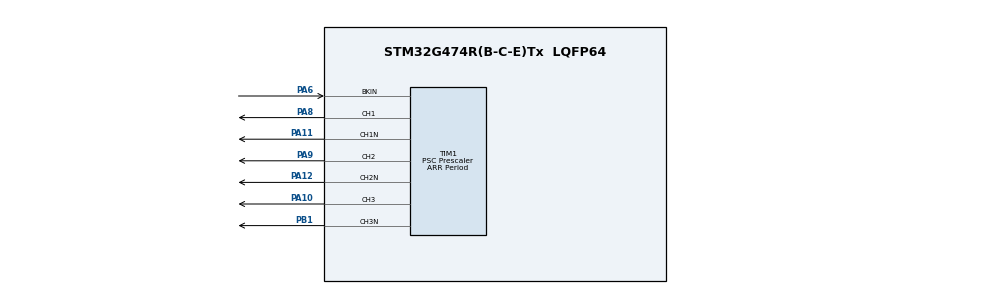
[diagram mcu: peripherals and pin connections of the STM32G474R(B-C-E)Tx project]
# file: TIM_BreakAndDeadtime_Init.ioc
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Mcu.Family=STM32G4
Mcu.Name=STM32G474R(B-C-E)Tx
Mcu.Package=LQFP64
NVIC.PriorityGroup=NVIC_PRIORITYGROUP_4
PA10.GPIO_Speed=GPIO_SPEED_FREQ_HIGH
PA10.Signal=S_TIM1_CH3
PA11.GPIO_Speed=GPIO_SPEED_FREQ_HIGH
PA11.Mode=PWM Generation1 CH1 CH1N
PA11.Signal=TIM1_CH1N
PA12.GPIO_Speed=GPIO_SPEED_FREQ_HIGH
PA12.Mode=PWM Generation2 CH2 CH2N
PA12.Signal=TIM1_CH2N
PA6.GPIO_PuPd=GPIO_PULLDOWN
PA6.GPIO_PuPdOD=GPIO_PULLDOWN
PA6.Mode=Activate-Break-Input
PA6.Signal=TIM1_BKIN
PA8.GPIO_Speed=GPIO_SPEED_FREQ_HIGH
PA8.Signal=S_TIM1_CH1
PA9.GPIO_Speed=GPIO_SPEED_FREQ_HIGH
PA9.Signal=S_TIM1_CH2
PB1.GPIO_Speed=GPIO_SPEED_FREQ_HIGH
PB1.Mode=PWM Generation3 CH3 CH3N
PB1.Signal=TIM1_CH3N
ProjectManager.HeapSize=0x200
ProjectManager.StackSize=0x400
ProjectManager.TargetToolchain=EWARM V8.32
RCC.ADC12Freq_Value=170000000
RCC.ADC345Freq_Value=170000000
RCC.AHBFreq_Value=170000000
RCC.APB1Freq_Value=170000000
RCC.APB1TimFreq_Value=170000000
RCC.APB2Freq_Value=170000000
RCC.APB2TimFreq_Value=170000000
RCC.CortexFreq_Value=170000000
RCC.EXTERNAL_CLOCK_VALUE=12288000
RCC.HCLKFreq_Value=170000000
RCC.HSE_VALUE=24000000
RCC.HSI48_VALUE=48000000
RCC.HSI_VALUE=16000000
RCC.LSE_VALUE=32768
RCC.PLLM=RCC_PLLM_DIV4
RCC.PLLN=85
RCC.SYSCLKFreq_VALUE=170000000
RCC.SYSCLKSource=RCC_SYSCLKSOURCE_PLLCLK
RCC.USBFreq_Value=170000000
RCC.VCOOutputFreq_Value=340000000
SH.S_TIM1_CH1.0=TIM1_CH1,PWM Generation1 CH1 CH1N
SH.S_TIM1_CH2.0=TIM1_CH2,PWM Generation2 CH2 CH2N
SH.S_TIM1_CH3.0=TIM1_CH3,PWM Generation3 CH3 CH3N
TIM1.AsymmetricalDeadTime=DISABLE
TIM1.AutoReloadPreload=TIM_AUTORELOAD_PRELOAD_DISABLE
TIM1.AutomaticOutput=TIM_AUTOMATICOUTPUT_ENABLE
TIM1.Break2Filter=0
TIM1.Break2Polarity=TIM_BREAK2POLARITY_HIGH
TIM1.Break2State=TIM_BREAK2_DISABLE
TIM1.BreakAFMode=TIM_BREAK_AFMODE_INPUT
TIM1.BreakFilter=0
TIM1.BreakPolarity=TIM_BREAKPOLARITY_HIGH
TIM1.BreakState=TIM_BREAK_ENABLE
TIM1.Channel-PWM\ Generation1\ CH1\ CH1N=TIM_CHANNEL_1
TIM1.Channel-PWM\ Generation2\ CH2\ CH2N=TIM_CHANNEL_2
TIM1.Channel-PWM\ Generation3\ CH3\ CH3N=TIM_CHANNEL_3
TIM1.ClearInputSource=TIM_CLEARINPUTSOURCE_NONE
TIM1.ClockDivision=TIM_CLOCKDIVISION_DIV1
TIM1.CounterMode=TIM_COUNTERMODE_CENTERALIGNED1
TIM1.DeadTime=Deadtime
TIM1.DeadTimePreload=DISABLE
TIM1.Dithering=Disable
TIM1.LockLevel=TIM_LOCKLEVEL_1
TIM1.OCFastMode_PWM-PWM\ Generation1\ CH1\ CH1N=TIM_OCFAST_DISABLE
TIM1.OCFastMode_PWM-PWM\ Generation2\ CH2\ CH2N=TIM_OCFAST_DISABLE
TIM1.OCFastMode_PWM-PWM\ Generation3\ CH3\ CH3N=TIM_OCFAST_DISABLE
TIM1.OCIdleState_1=TIM_OCIDLESTATE_RESET
TIM1.OCIdleState_2=TIM_OCIDLESTATE_RESET
TIM1.OCIdleState_3=TIM_OCIDLESTATE_RESET
TIM1.OCMode_PWM-PWM\ Generation1\ CH1\ CH1N=TIM_OCMODE_PWM1
TIM1.OCMode_PWM-PWM\ Generation2\ CH2\ CH2N=TIM_OCMODE_PWM1
TIM1.OCMode_PWM-PWM\ Generation3\ CH3\ CH3N=TIM_OCMODE_PWM1
TIM1.OCNIdleState_1=TIM_OCNIDLESTATE_RESET
TIM1.OCNIdleState_2=TIM_OCNIDLESTATE_RESET
TIM1.OCNIdleState_3=TIM_OCNIDLESTATE_RESET
TIM1.OCNPolarity_1=TIM_OCNPOLARITY_HIGH
TIM1.OCNPolarity_2=TIM_OCNPOLARITY_HIGH
TIM1.OCNPolarity_3=TIM_OCNPOLARITY_HIGH
TIM1.OCPolarity_1=TIM_OCPOLARITY_HIGH
TIM1.OCPolarity_2=TIM_OCPOLARITY_HIGH
TIM1.OCPolarity_3=TIM_OCPOLARITY_HIGH
TIM1.OffStateIDLEMode=TIM_OSSI_ENABLE
TIM1.OffStateRunMode=TIM_OSSR_ENABLE
TIM1.PeriodNoDither=Period
TIM1.Prescaler=Prescaler
TIM1.PulseNoDither_1=Pulse1
TIM1.PulseNoDither_2=Pulse2
TIM1.PulseNoDither_3=Pulse3
TIM1.RepetitionCounter=0
TIM1.SourceBRK2COMP1=TIM_BREAKINPUTSOURCE_DISABLE
TIM1.SourceBRK2COMP2=TIM_BREAKINPUTSOURCE_DISABLE
TIM1.SourceBRK2COMP3=TIM_BREAKINPUTSOURCE_DISABLE
TIM1.SourceBRK2COMP4=TIM_BREAKINPUTSOURCE_DISABLE
TIM1.SourceBRK2COMP5=TIM_BREAKINPUTSOURCE_DISABLE
TIM1.SourceBRK2COMP6=TIM_BREAKINPUTSOURCE_DISABLE
TIM1.SourceBRK2COMP7=TIM_BREAKINPUTSOURCE_DISABLE
TIM1.SourceBRK2DigInput=TIM_BREAKINPUTSOURCE_DISABLE
TIM1.SourceBRKCOMP1=TIM_BREAKINPUTSOURCE_DISABLE
TIM1.SourceBRKCOMP2=TIM_BREAKINPUTSOURCE_DISABLE
TIM1.SourceBRKCOMP3=TIM_BREAKINPUTSOURCE_DISABLE
TIM1.SourceBRKCOMP4=TIM_BREAKINPUTSOURCE_DISABLE
TIM1.SourceBRKCOMP5=TIM_BREAKINPUTSOURCE_DISABLE
TIM1.SourceBRKCOMP6=TIM_BREAKINPUTSOURCE_DISABLE
TIM1.SourceBRKCOMP7=TIM_BREAKINPUTSOURCE_DISABLE
TIM1.SourceBRKDigInput=TIM_BREAKINPUTSOURCE_ENABLE
TIM1.SourceBRKDigInputPolarity=TIM_BREAKINPUTSOURCE_POLARITY_HIGH
TIM1.TIM_MasterOutputTrigger=TIM_TRGO_RESET
TIM1.TIM_MasterOutputTrigger2=TIM_TRGO2_RESET
TIM1.TIM_MasterSlaveMode=TIM_MASTERSLAVEMODE_DISABLE
VP_SYS_VS_DBSignals.Mode=DisableDeadBatterySignals
board=custom

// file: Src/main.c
/* USER CODE BEGIN Header */
/**
  ******************************************************************************
  * @file           : main.c
  * @brief          : Main program body
  ******************************************************************************
  * @attention
  *
  * Copyright (c) 2019-2021 STMicroelectronics.
  * All rights reserved.
  *
  * This software is licensed under terms that can be found in the LICENSE file
  * in the root directory of this software component.
  * If no LICENSE file comes with this software, it is provided AS-IS.
  *
  ******************************************************************************
  */
/* USER CODE END Header */
#include "main.h"

void SystemClock_Config(void);
static void MX_GPIO_Init(void);
static void MX_TIM1_Init(void);

int main(void)
{

  /* MCU Configuration--------------------------------------------------------*/

  /* Reset of all peripherals, Initializes the Flash interface and the Systick. */

  LL_APB2_GRP1_EnableClock(LL_APB2_GRP1_PERIPH_SYSCFG);
  LL_APB1_GRP1_EnableClock(LL_APB1_GRP1_PERIPH_PWR);

  NVIC_SetPriorityGrouping(NVIC_PRIORITYGROUP_4);

  /* System interrupt init*/

  /** Disable the internal Pull-Up in Dead Battery pins of UCPD peripheral
  */
  LL_PWR_DisableUCPDDeadBattery();

  /* Configure the system clock */
  SystemClock_Config();

  /* Initialize all configured peripherals */
  MX_GPIO_Init();
  MX_TIM1_Init();
  /* USER CODE BEGIN 2 */

  /**********************************/
  /* Start output signal generation */
  /**********************************/
  /* Enable outputs OC1, OC1N, OC2, OC2N, OC3 and OC3N */
  LL_TIM_CC_EnableChannel(TIM1, LL_TIM_CHANNEL_CH1  |
                                LL_TIM_CHANNEL_CH1N |
                                LL_TIM_CHANNEL_CH2  |
                                LL_TIM_CHANNEL_CH2N |
                                LL_TIM_CHANNEL_CH3  |
                                LL_TIM_CHANNEL_CH3N);

  /* Enable counter */
  LL_TIM_EnableCounter(TIM1);

  /* Force update generation */
  LL_TIM_GenerateEvent_UPDATE(TIM1);

  /* USER CODE END 2 */

  /* Infinite loop */
  while (1)
  {

  }
}

void SystemClock_Config(void)
{
  LL_FLASH_SetLatency(LL_FLASH_LATENCY_4);
  while(LL_FLASH_GetLatency() != LL_FLASH_LATENCY_4)
  {
  }
  LL_PWR_EnableRange1BoostMode();
  LL_RCC_HSI_Enable();
   /* Wait till HSI is ready */
  while(LL_RCC_HSI_IsReady() != 1)
  {
  }

  LL_RCC_HSI_SetCalibTrimming(64);
  LL_RCC_PLL_ConfigDomain_SYS(LL_RCC_PLLSOURCE_HSI, LL_RCC_PLLM_DIV_4, 85, LL_RCC_PLLR_DIV_2);
  LL_RCC_PLL_EnableDomain_SYS();
  LL_RCC_PLL_Enable();
   /* Wait till PLL is ready */
  while(LL_RCC_PLL_IsReady() != 1)
  {
  }

  LL_RCC_SetSysClkSource(LL_RCC_SYS_CLKSOURCE_PLL);
  LL_RCC_SetAHBPrescaler(LL_RCC_SYSCLK_DIV_2);
   /* Wait till System clock is ready */
  while(LL_RCC_GetSysClkSource() != LL_RCC_SYS_CLKSOURCE_STATUS_PLL)
  {
  }

  /* Insure 1µs transition state at intermediate medium speed clock based on DWT */
  CoreDebug->DEMCR |= CoreDebug_DEMCR_TRCENA_Msk;
  DWT->CTRL |= DWT_CTRL_CYCCNTENA_Msk;
  DWT->CYCCNT = 0;
  while(DWT->CYCCNT < 100);
  /* Set AHB prescaler*/
  LL_RCC_SetAHBPrescaler(LL_RCC_SYSCLK_DIV_1);
  LL_RCC_SetAPB1Prescaler(LL_RCC_APB1_DIV_1);
  LL_RCC_SetAPB2Prescaler(LL_RCC_APB2_DIV_1);

  LL_Init1msTick(170000000);

  LL_SetSystemCoreClock(170000000);
}

static void MX_TIM1_Init(void)
{

  /* USER CODE BEGIN TIM1_Init 0 */
  uint32_t Prescaler = __LL_TIM_CALC_PSC(SystemCoreClock, 10000000);
  uint32_t Period = __LL_TIM_CALC_ARR(SystemCoreClock, Prescaler, 10000*2);
  uint32_t Pulse1 = (Period * 500) / 1000;
  uint32_t Pulse2 = (Period * 250) / 1000;
  uint32_t Pulse3 = (Period * 125) / 1000;
  uint32_t Deadtime = __LL_TIM_CALC_DEADTIME(SystemCoreClock, LL_TIM_CLOCKDIVISION_DIV1, 4000);

  /* USER CODE END TIM1_Init 0 */

  LL_TIM_InitTypeDef TIM_InitStruct = {0};
  LL_TIM_OC_InitTypeDef TIM_OC_InitStruct = {0};
  LL_TIM_BDTR_InitTypeDef TIM_BDTRInitStruct = {0};

  LL_GPIO_InitTypeDef GPIO_InitStruct = {0};

  /* Peripheral clock enable */
  LL_APB2_GRP1_EnableClock(LL_APB2_GRP1_PERIPH_TIM1);

  LL_AHB2_GRP1_EnableClock(LL_AHB2_GRP1_PERIPH_GPIOA);
  /**TIM1 GPIO Configuration
  PA6   ------> TIM1_BKIN
  */
  GPIO_InitStruct.Pin = LL_GPIO_PIN_6;
  GPIO_InitStruct.Mode = LL_GPIO_MODE_ALTERNATE;
  GPIO_InitStruct.Speed = LL_GPIO_SPEED_FREQ_LOW;
  GPIO_InitStruct.OutputType = LL_GPIO_OUTPUT_OPENDRAIN;
  GPIO_InitStruct.Pull = LL_GPIO_PULL_DOWN;
  GPIO_InitStruct.Alternate = LL_GPIO_AF_6;
  LL_GPIO_Init(GPIOA, &GPIO_InitStruct);

  TIM_InitStruct.Prescaler = Prescaler;
  TIM_InitStruct.CounterMode = LL_TIM_COUNTERMODE_CENTER_UP;
  TIM_InitStruct.Autoreload = Period;
  TIM_InitStruct.ClockDivision = LL_TIM_CLOCKDIVISION_DIV1;
  TIM_InitStruct.RepetitionCounter = 0;
  LL_TIM_Init(TIM1, &TIM_InitStruct);
  LL_TIM_DisableARRPreload(TIM1);
  LL_TIM_OC_EnablePreload(TIM1, LL_TIM_CHANNEL_CH1);
  TIM_OC_InitStruct.OCMode = LL_TIM_OCMODE_PWM1;
  TIM_OC_InitStruct.OCState = LL_TIM_OCSTATE_DISABLE;
  TIM_OC_InitStruct.OCNState = LL_TIM_OCSTATE_DISABLE;
  TIM_OC_InitStruct.CompareValue = Pulse1;
  TIM_OC_InitStruct.OCPolarity = LL_TIM_OCPOLARITY_HIGH;
  TIM_OC_InitStruct.OCNPolarity = LL_TIM_OCPOLARITY_HIGH;
  TIM_OC_InitStruct.OCIdleState = LL_TIM_OCIDLESTATE_LOW;
  TIM_OC_InitStruct.OCNIdleState = LL_TIM_OCIDLESTATE_LOW;
  LL_TIM_OC_Init(TIM1, LL_TIM_CHANNEL_CH1, &TIM_OC_InitStruct);
  LL_TIM_OC_DisableFast(TIM1, LL_TIM_CHANNEL_CH1);
  LL_TIM_OC_EnablePreload(TIM1, LL_TIM_CHANNEL_CH2);
  TIM_OC_InitStruct.CompareValue = Pulse2;
  LL_TIM_OC_Init(TIM1, LL_TIM_CHANNEL_CH2, &TIM_OC_InitStruct);
  LL_TIM_OC_DisableFast(TIM1, LL_TIM_CHANNEL_CH2);
  LL_TIM_OC_EnablePreload(TIM1, LL_TIM_CHANNEL_CH3);
  TIM_OC_InitStruct.CompareValue = Pulse3;
  LL_TIM_OC_Init(TIM1, LL_TIM_CHANNEL_CH3, &TIM_OC_InitStruct);
  LL_TIM_OC_DisableFast(TIM1, LL_TIM_CHANNEL_CH3);
  LL_TIM_SetTriggerOutput(TIM1, LL_TIM_TRGO_RESET);
  LL_TIM_SetTriggerOutput2(TIM1, LL_TIM_TRGO2_RESET);
  LL_TIM_DisableMasterSlaveMode(TIM1);
  LL_TIM_SetBreakInputSourcePolarity(TIM1, LL_TIM_BREAK_INPUT_BKIN, LL_TIM_BKIN_SOURCE_BKIN, LL_TIM_BKIN_POLARITY_HIGH);
  TIM_BDTRInitStruct.OSSRState = LL_TIM_OSSR_ENABLE;
  TIM_BDTRInitStruct.OSSIState = LL_TIM_OSSI_ENABLE;
  TIM_BDTRInitStruct.LockLevel = LL_TIM_LOCKLEVEL_1;
  TIM_BDTRInitStruct.DeadTime = Deadtime;
  TIM_BDTRInitStruct.BreakState = LL_TIM_BREAK_ENABLE;
  TIM_BDTRInitStruct.BreakPolarity = LL_TIM_BREAK_POLARITY_HIGH;
  TIM_BDTRInitStruct.BreakFilter = LL_TIM_BREAK_FILTER_FDIV1;
  TIM_BDTRInitStruct.BreakAFMode = LL_TIM_BREAK_AFMODE_INPUT;
  TIM_BDTRInitStruct.Break2State = LL_TIM_BREAK2_DISABLE;
  TIM_BDTRInitStruct.Break2Polarity = LL_TIM_BREAK2_POLARITY_HIGH;
  TIM_BDTRInitStruct.Break2Filter = LL_TIM_BREAK2_FILTER_FDIV1;
  TIM_BDTRInitStruct.Break2AFMode = LL_TIM_BREAK_AFMODE_INPUT;
  TIM_BDTRInitStruct.AutomaticOutput = LL_TIM_AUTOMATICOUTPUT_ENABLE;
  LL_TIM_BDTR_Init(TIM1, &TIM_BDTRInitStruct);
  LL_AHB2_GRP1_EnableClock(LL_AHB2_GRP1_PERIPH_GPIOB);
  LL_AHB2_GRP1_EnableClock(LL_AHB2_GRP1_PERIPH_GPIOA);
  /**TIM1 GPIO Configuration
  PB1   ------> TIM1_CH3N
  PA8   ------> TIM1_CH1
  PA9   ------> TIM1_CH2
  PA10   ------> TIM1_CH3
  PA11   ------> TIM1_CH1N
  PA12   ------> TIM1_CH2N
  */
  GPIO_InitStruct.Pin = LL_GPIO_PIN_1;
  GPIO_InitStruct.Mode = LL_GPIO_MODE_ALTERNATE;
  GPIO_InitStruct.Speed = LL_GPIO_SPEED_FREQ_HIGH;
  GPIO_InitStruct.OutputType = LL_GPIO_OUTPUT_PUSHPULL;
  GPIO_InitStruct.Pull = LL_GPIO_PULL_NO;
  GPIO_InitStruct.Alternate = LL_GPIO_AF_6;
  LL_GPIO_Init(GPIOB, &GPIO_InitStruct);

  GPIO_InitStruct.Pin = LL_GPIO_PIN_8;
  GPIO_InitStruct.Mode = LL_GPIO_MODE_ALTERNATE;
  GPIO_InitStruct.Speed = LL_GPIO_SPEED_FREQ_HIGH;
  GPIO_InitStruct.OutputType = LL_GPIO_OUTPUT_PUSHPULL;
  GPIO_InitStruct.Pull = LL_GPIO_PULL_NO;
  GPIO_InitStruct.Alternate = LL_GPIO_AF_6;
  LL_GPIO_Init(GPIOA, &GPIO_InitStruct);

  GPIO_InitStruct.Pin = LL_GPIO_PIN_9;
  GPIO_InitStruct.Mode = LL_GPIO_MODE_ALTERNATE;
  GPIO_InitStruct.Speed = LL_GPIO_SPEED_FREQ_HIGH;
  GPIO_InitStruct.OutputType = LL_GPIO_OUTPUT_PUSHPULL;
  GPIO_InitStruct.Pull = LL_GPIO_PULL_NO;
  GPIO_InitStruct.Alternate = LL_GPIO_AF_6;
  LL_GPIO_Init(GPIOA, &GPIO_InitStruct);

  GPIO_InitStruct.Pin = LL_GPIO_PIN_10;
  GPIO_InitStruct.Mode = LL_GPIO_MODE_ALTERNATE;
  GPIO_InitStruct.Speed = LL_GPIO_SPEED_FREQ_HIGH;
  GPIO_InitStruct.OutputType = LL_GPIO_OUTPUT_PUSHPULL;
  GPIO_InitStruct.Pull = LL_GPIO_PULL_NO;
  GPIO_InitStruct.Alternate = LL_GPIO_AF_6;
  LL_GPIO_Init(GPIOA, &GPIO_InitStruct);

  GPIO_InitStruct.Pin = LL_GPIO_PIN_11;
  GPIO_InitStruct.Mode = LL_GPIO_MODE_ALTERNATE;
  GPIO_InitStruct.Speed = LL_GPIO_SPEED_FREQ_HIGH;
  GPIO_InitStruct.OutputType = LL_GPIO_OUTPUT_PUSHPULL;
  GPIO_InitStruct.Pull = LL_GPIO_PULL_NO;
  GPIO_InitStruct.Alternate = LL_GPIO_AF_6;
  LL_GPIO_Init(GPIOA, &GPIO_InitStruct);

  GPIO_InitStruct.Pin = LL_GPIO_PIN_12;
  GPIO_InitStruct.Mode = LL_GPIO_MODE_ALTERNATE;
  GPIO_InitStruct.Speed = LL_GPIO_SPEED_FREQ_HIGH;
  GPIO_InitStruct.OutputType = LL_GPIO_OUTPUT_PUSHPULL;
  GPIO_InitStruct.Pull = LL_GPIO_PULL_NO;
  GPIO_InitStruct.Alternate = LL_GPIO_AF_6;
  LL_GPIO_Init(GPIOA, &GPIO_InitStruct);

}

static void MX_GPIO_Init(void)
{

  /* GPIO Ports Clock Enable */
  LL_AHB2_GRP1_EnableClock(LL_AHB2_GRP1_PERIPH_GPIOA);
  LL_AHB2_GRP1_EnableClock(LL_AHB2_GRP1_PERIPH_GPIOB);

}

void Error_Handler(void)
{
}
